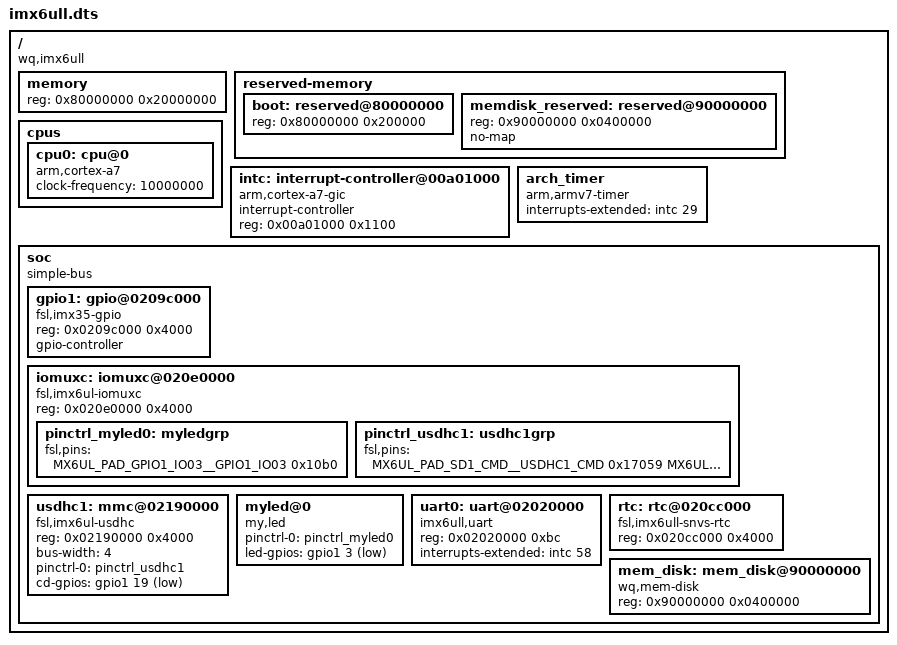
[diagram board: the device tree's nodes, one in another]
#include <dt-bindings/gpio/gpio.h>
#include "imx6ull-pinfunc.h"
/dts-v1/;
/ {
    #address-cells = <1>;
    #size-cells = <1>;
    compatible = "wq,imx6ull";

    memory {
        device_type = "memory";
        reg = < 0x80000000 0x20000000 >; // 内存起始地址和大小
    };

    reserved-memory {
        #address-cells = <1>;
        #size-cells = <1>;
        ranges;
        boot: reserved@80000000 {
            reg = <0x80000000 0x200000>; // 保留内存区域
        };
        memdisk_reserved: reserved@90000000 {
            reg = <0x90000000 0x0400000>; // 给 mem_disk 预留 4MB
            no-map;
        };
    };

    cpus {
        #address-cells = <1>;
        #size-cells = <1>;
        cpu0: cpu@0 {
            compatible = "arm,cortex-a7";
            device_type = "cpu";
            clock-frequency = <10000000>;
        };
    };

    intc:interrupt-controller@00a01000 {
        compatible = "arm,cortex-a7-gic";
        #interrupt-cells = <1>;
        interrupt-controller;
        reg =   <0x00a01000 0x1100>;
    };

    arch_timer {
        compatible = "arm,armv7-timer";
        interrupts-extended = <&intc 29>;
    };

    soc {
        #address-cells = <1>;
        #size-cells = <1>;
        compatible = "simple-bus";

        gpio1: gpio@0209c000 {
            compatible = "fsl,imx35-gpio";
            reg = <0x0209c000 0x4000>;
            // interrupts-extended = <&intc 66 IRQ_TYPE_LEVEL_HIGH>,
            //             <&intc 67 IRQ_TYPE_LEVEL_HIGH>;
            gpio-controller;
            #gpio-cells = <2>;
            // interrupt-controller;
            // #interrupt-cells = <2>;
		};

        iomuxc: iomuxc@020e0000 {
            compatible = "fsl,imx6ul-iomuxc";
            reg = <0x020e0000 0x4000>;

            pinctrl_myled0: myledgrp {
                fsl,pins = <
                    MX6UL_PAD_GPIO1_IO03__GPIO1_IO03 0x10b0
                >;
            };

            pinctrl_usdhc1: usdhc1grp {
                fsl,pins = <
                    MX6UL_PAD_SD1_CMD__USDHC1_CMD     0x17059
                    MX6UL_PAD_SD1_CLK__USDHC1_CLK     0x10071
                    MX6UL_PAD_SD1_DATA0__USDHC1_DATA0 0x17059
                    MX6UL_PAD_SD1_DATA1__USDHC1_DATA1 0x17059
                    MX6UL_PAD_SD1_DATA2__USDHC1_DATA2 0x17059
                    MX6UL_PAD_SD1_DATA3__USDHC1_DATA3 0x17059
                >;
		    };
        };

        usdhc1: mmc@02190000 {
            compatible = "fsl,imx6ul-usdhc", "fsl,imx6sx-usdhc";
			reg = <0x02190000 0x4000>;
            bus-width = <4>;
            pinctrl-names = "default";
            pinctrl-0 = <&pinctrl_usdhc1>;
            cd-gpios = <&gpio1 19 GPIO_ACTIVE_LOW>;
      
            status = "okay";
        };
       
  // setenv kernel_addr_r 0x80200000; tftp ${kernel_addr_r} uImage; setexpr kernel_end ${kernel_addr_r} + ${filesize}; setexpr fdt_addr_r ${kernel_end} + 0x400000; setexpr fdt_addr_r ${fdt_addr_r} + 0x1fffff; setexpr fdt_addr_r ${fdt_addr_r} "&" 0xffe00000; tftp ${fdt_addr_r} imx6ull.dtb; tftp 0x90000000 rootfs.ext2 bootm ${kernel_addr_r} - ${fdt_addr_r}
        myled@0 {
            compatible = "my,led";
            pinctrl-names = "default";
            pinctrl-0 = <&pinctrl_myled0>;
            led-gpios = <&gpio1 3 GPIO_ACTIVE_LOW>;
	    };
        
        uart0: uart@02020000 {
            compatible = "imx6ull,uart";
            reg = <0x02020000 0xbc>;
            interrupts-extended = <&intc 58>; // GIC中对应的中断号
        };

        rtc: rtc@020cc000 {
            compatible = "fsl,imx6ull-snvs-rtc";
            reg = <0x020cc000 0x4000>;
        };

        mem_disk: mem_disk@90000000 {
            compatible = "wq,mem-disk";
            reg = <0x90000000 0x0400000>;
            status = "okay";
        };
    };
};
